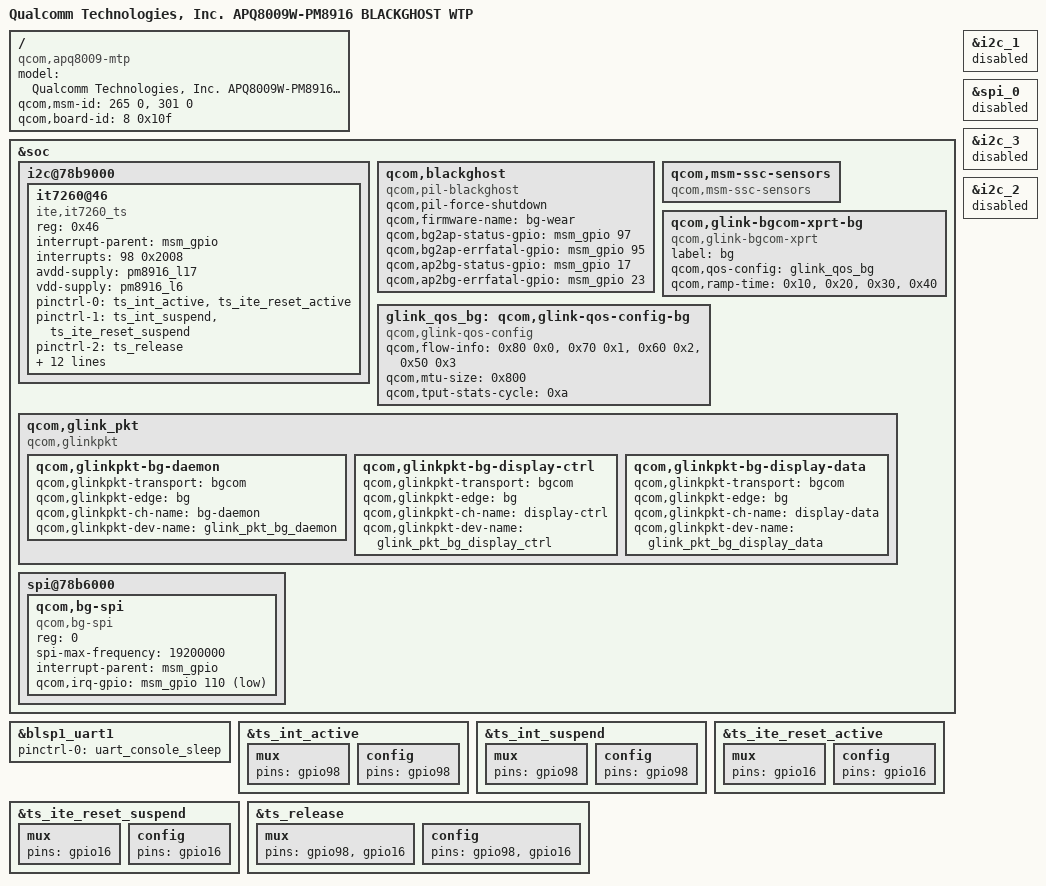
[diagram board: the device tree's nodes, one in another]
/*
 * Copyright (c) 2017, 2018 The Linux Foundation. All rights reserved.
 *
 * This program is free software; you can redistribute it and/or modify
 * it under the terms of the GNU General Public License version 2 and
 * only version 2 as published by the Free Software Foundation.
 *
 * This program is distributed in the hope that it will be useful,
 * but WITHOUT ANY WARRANTY; without even the implied warranty of
 * MERCHANTABILITY or FITNESS FOR A PARTICULAR PURPOSE.  See the
 * GNU General Public License for more details.
 */

/dts-v1/;

#include "msm8909-mtp.dtsi"
#include "msm8909w-gpu.dtsi"
#include "msm8909-pm8916.dtsi"
#include "msm8909-pm8916-mtp.dtsi"
#include "msm8909w.dtsi"
#include "apq8009w-bg-memory.dtsi"

/ {
	model = "Qualcomm Technologies, Inc. APQ8009W-PM8916 BLACKGHOST WTP";
	compatible = "qcom,apq8009-mtp", "qcom,apq8009", "qcom,mtp";
	qcom,msm-id =   <265 0>,
			<301 0>;
	qcom,board-id = <8 0x10f>;
};

&soc {
	i2c@78b9000 { /* BLSP1 QUP5 */
		/delete-node/ synaptics@20;

		it7260@46 {
			compatible = "ite,it7260_ts";
			reg = <0x46>;
			interrupt-parent = <&msm_gpio>;
			interrupts = <98 0x2008>;
			avdd-supply = <&pm8916_l17>;
			vdd-supply = <&pm8916_l6>;
			/* pins used by touchscreen */
			pinctrl-names = "pmx_ts_active", "pmx_ts_suspend",
							"pmx_ts_release";
			pinctrl-0 = <&ts_int_active &ts_ite_reset_active>;
			pinctrl-1 = <&ts_int_suspend &ts_ite_reset_suspend>;
			pinctrl-2 = <&ts_release>;
			ite,reset-gpio = <&msm_gpio 16 0x00>;
			ite,irq-gpio = <&msm_gpio 98 0x2008>;
			ite,panel-coords = <0 0 320 320>;
			ite,display-coords = <0 0 320 320>;
			ite,reset-delay = <20>;
			ite,num-fingers = <2>;
			ite,wakeup;
			ite,palm-detect-en;
			ite,palm-detect-keycode = <142>;
			ite,fw-name = "it7260_fw_050D0014.bin";
			ite,cfg-name = "it7260_cfg_62011E01.bin";
			ite,avdd-lpm-cur = <3000>;
		};
	};

	qcom,blackghost {
		compatible = "qcom,pil-blackghost";

		qcom,pil-force-shutdown;
		qcom,firmware-name = "bg-wear";
		/* GPIO inputs from blackghost */
		qcom,bg2ap-status-gpio = <&msm_gpio 97 0>;
		qcom,bg2ap-errfatal-gpio = <&msm_gpio 95 0>;
		/* GPIO output to blackghost */
		qcom,ap2bg-status-gpio = <&msm_gpio 17 0>;
		qcom,ap2bg-errfatal-gpio = <&msm_gpio 23 0>;
	};

	qcom,msm-ssc-sensors {
		compatible = "qcom,msm-ssc-sensors";
	};

	qcom,glink-bgcom-xprt-bg {
		compatible = "qcom,glink-bgcom-xprt";
		label = "bg";
		qcom,qos-config = <&glink_qos_bg>;
		qcom,ramp-time = <0x10>,
				     <0x20>,
				     <0x30>,
				     <0x40>;
	};

	glink_qos_bg: qcom,glink-qos-config-bg {
		compatible = "qcom,glink-qos-config";
		qcom,flow-info = <0x80 0x0>,
				 <0x70 0x1>,
				 <0x60 0x2>,
				 <0x50 0x3>;
		qcom,mtu-size = <0x800>;
		qcom,tput-stats-cycle = <0xa>;
	};

	qcom,glink_pkt {
		compatible = "qcom,glinkpkt";

		qcom,glinkpkt-bg-daemon {
			qcom,glinkpkt-transport = "bgcom";
			qcom,glinkpkt-edge = "bg";
			qcom,glinkpkt-ch-name = "bg-daemon";
			qcom,glinkpkt-dev-name = "glink_pkt_bg_daemon";
		};

		qcom,glinkpkt-bg-display-ctrl {
			qcom,glinkpkt-transport = "bgcom";
			qcom,glinkpkt-edge = "bg";
			qcom,glinkpkt-ch-name = "display-ctrl";
			qcom,glinkpkt-dev-name = "glink_pkt_bg_display_ctrl";
		};

		qcom,glinkpkt-bg-display-data {
			qcom,glinkpkt-transport = "bgcom";
			qcom,glinkpkt-edge = "bg";
			qcom,glinkpkt-ch-name = "display-data";
			qcom,glinkpkt-dev-name = "glink_pkt_bg_display_data";
		};
	};
};

&i2c_1 {
	status = "disabled";
};

&spi_0 {
	status = "disabled";
};

&i2c_3 {
	status = "disabled";
};

&i2c_2 {
	status = "disabled";
};

&blsp1_uart1 {
	status = "ok";
	pinctrl-names = "default";
	pinctrl-0 = <&uart_console_sleep>;
};

&soc
{
	spi@78b6000 { /* BLSP1 QUP2 */
		status = "ok";
		qcom,bg-spi {
			compatible = "qcom,bg-spi";
			reg = <0>;
			spi-max-frequency = <19200000>;
			interrupt-parent = <&msm_gpio>;
			qcom,irq-gpio = <&msm_gpio 110 1>;
		};
	};
};

/* Pinctrl dt nodes for interrupt and reset gpio for ITE tech controller */
&ts_int_active {
	mux {
		pins = "gpio98";
	};

	config {
		pins = "gpio98";
	};
};

&ts_int_suspend {
	mux {
		pins = "gpio98";
	};

	config {
		pins = "gpio98";
	};
};

&ts_ite_reset_active {
	mux {
		pins = "gpio16";
	};

	config {
		pins = "gpio16";
	};
};

&ts_ite_reset_suspend {
	mux {
		pins = "gpio16";
	};

	config {
		pins = "gpio16";
	};
};

&ts_release {
	mux {
		pins = "gpio98", "gpio16";
	};

	config {
		pins = "gpio98", "gpio16";
	};
};
